# TM4C123AH6PM register map
Vendor: Texas Instruments; File version: 11073
CPU: CM4 r1p2, little endian, no MPU, no FPU, 0x3 interrupt priority bits, 0x0 interrupts
Registers are 32-bit, read-write, no defined reset value unless marked. A register's access mark holds for its fields unless they carry their own. Offsets are from the block's base; [hi:lo] are bit positions; {n}, {i} and the like mark numbered series.

## COMP — Register map for COMP peripheral
Base 0x4003C000; register names take the prefix COMP
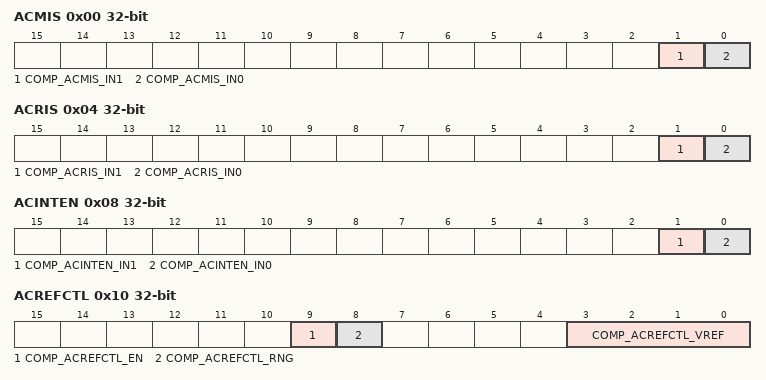
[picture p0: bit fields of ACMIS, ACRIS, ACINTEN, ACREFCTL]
0x00 ACMIS — Analog Comparator Masked Interrupt Status
  [1] COMP_ACMIS_IN1 — Comparator 1 Masked Interrupt Status
  [0] COMP_ACMIS_IN0 — Comparator 0 Masked Interrupt Status
0x04 ACRIS — Analog Comparator Raw Interrupt Status
  [1] COMP_ACRIS_IN1 — Comparator 1 Interrupt Status
  [0] COMP_ACRIS_IN0 — Comparator 0 Interrupt Status
0x08 ACINTEN — Analog Comparator Interrupt Enable
  [1] COMP_ACINTEN_IN1 — Comparator 1 Interrupt Enable
  [0] COMP_ACINTEN_IN0 — Comparator 0 Interrupt Enable
0x10 ACREFCTL — Analog Comparator Reference Voltage Control
  [9] COMP_ACREFCTL_EN — Resistor Ladder Enable
  [8] COMP_ACREFCTL_RNG — Resistor Ladder Range
  [3:0] COMP_ACREFCTL_VREF — Resistor Ladder Voltage Ref
0x20 ACSTAT0 — Analog Comparator Status 0
  [1] COMP_ACSTAT0_OVAL — Comparator Output Value
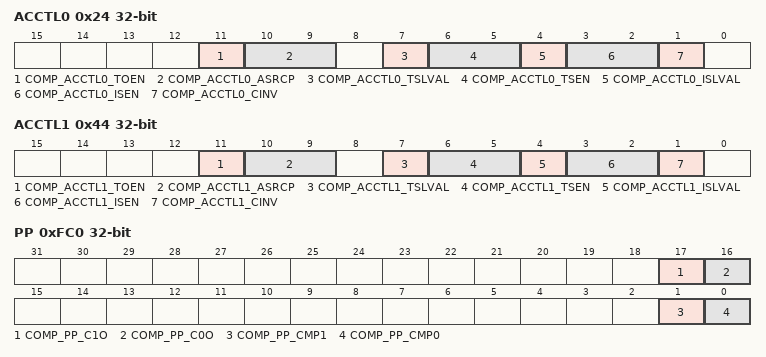
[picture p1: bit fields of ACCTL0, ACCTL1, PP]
0x24 ACCTL0 — Analog Comparator Control 0
  [11] COMP_ACCTL0_TOEN — Trigger Output Enable
  [10:9] COMP_ACCTL0_ASRCP — Analog Source Positive
    0=COMP_ACCTL0_ASRCP_PIN (Pin value of Cn+); 1=COMP_ACCTL0_ASRCP_PIN0 (Pin value of C0+); 2=COMP_ACCTL0_ASRCP_REF (Internal voltage reference)
  [7] COMP_ACCTL0_TSLVAL — Trigger Sense Level Value
  [6:5] COMP_ACCTL0_TSEN — Trigger Sense
    0=COMP_ACCTL0_TSEN_LEVEL (Level sense, see TSLVAL); 1=COMP_ACCTL0_TSEN_FALL (Falling edge); 2=COMP_ACCTL0_TSEN_RISE (Rising edge); 3=COMP_ACCTL0_TSEN_BOTH (Either edge)
  [4] COMP_ACCTL0_ISLVAL — Interrupt Sense Level Value
  [3:2] COMP_ACCTL0_ISEN — Interrupt Sense
    0=COMP_ACCTL0_ISEN_LEVEL (Level sense, see ISLVAL); 1=COMP_ACCTL0_ISEN_FALL (Falling edge); 2=COMP_ACCTL0_ISEN_RISE (Rising edge); 3=COMP_ACCTL0_ISEN_BOTH (Either edge)
  [1] COMP_ACCTL0_CINV — Comparator Output Invert
0x40 ACSTAT1 — Analog Comparator Status 1
  [1] COMP_ACSTAT1_OVAL — Comparator Output Value
0x44 ACCTL1 — Analog Comparator Control 1
  [11] COMP_ACCTL1_TOEN — Trigger Output Enable
  [10:9] COMP_ACCTL1_ASRCP — Analog Source Positive
    0=COMP_ACCTL1_ASRCP_PIN (Pin value of Cn+); 1=COMP_ACCTL1_ASRCP_PIN0 (Pin value of C0+); 2=COMP_ACCTL1_ASRCP_REF (Internal voltage reference (VIREF))
  [7] COMP_ACCTL1_TSLVAL — Trigger Sense Level Value
  [6:5] COMP_ACCTL1_TSEN — Trigger Sense
    0=COMP_ACCTL1_TSEN_LEVEL (Level sense, see TSLVAL); 1=COMP_ACCTL1_TSEN_FALL (Falling edge); 2=COMP_ACCTL1_TSEN_RISE (Rising edge); 3=COMP_ACCTL1_TSEN_BOTH (Either edge)
  [4] COMP_ACCTL1_ISLVAL — Interrupt Sense Level Value
  [3:2] COMP_ACCTL1_ISEN — Interrupt Sense
    0=COMP_ACCTL1_ISEN_LEVEL (Level sense, see ISLVAL); 1=COMP_ACCTL1_ISEN_FALL (Falling edge); 2=COMP_ACCTL1_ISEN_RISE (Rising edge); 3=COMP_ACCTL1_ISEN_BOTH (Either edge)
  [1] COMP_ACCTL1_CINV — Comparator Output Invert
0xFC0 PP — Analog Comparator Peripheral Properties
  [17] COMP_PP_C1O — Comparator Output 1 Present
  [16] COMP_PP_C0O — Comparator Output 0 Present
  [1] COMP_PP_CMP1 — Comparator 1 Present
  [0] COMP_PP_CMP0 — Comparator 0 Present

## EEPROM — Register map for EEPROM peripheral
Base 0x400AF000; register names take the prefix EEPROM
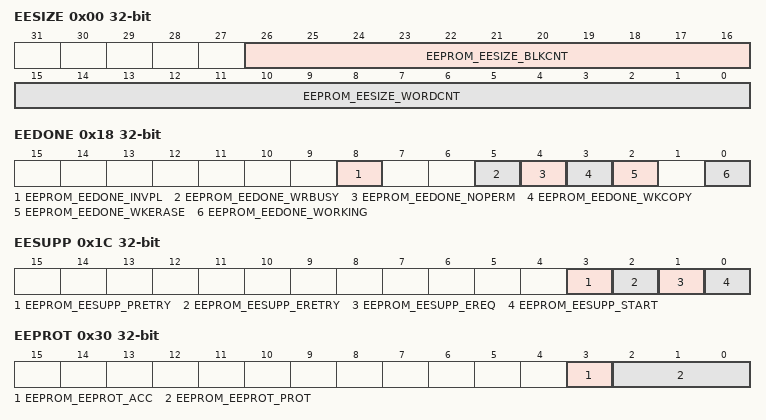
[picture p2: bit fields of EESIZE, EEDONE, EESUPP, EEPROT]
0x00 EESIZE — EEPROM Size Information
  [26:16] EEPROM_EESIZE_BLKCNT — Number of 16-Word Blocks
  [15:0] EEPROM_EESIZE_WORDCNT — Number of 32-Bit Words
0x04 EEBLOCK — EEPROM Current Block
  [15:0] EEPROM_EEBLOCK_BLOCK — Current Block
0x08 EEOFFSET — EEPROM Current Offset
  [3:0] EEPROM_EEOFFSET_OFFSET — Current Address Offset
0x10 EERDWR — EEPROM Read-Write
  [31:0] EEPROM_EERDWR_VALUE — EEPROM Read or Write Data
0x14 EERDWRINC — EEPROM Read-Write with Increment
  [31:0] EEPROM_EERDWRINC_VALUE — EEPROM Read or Write Data with Increment
0x18 EEDONE — EEPROM Done Status
  [8] EEPROM_EEDONE_INVPL — Invalid Program Voltage Level
  [5] EEPROM_EEDONE_WRBUSY — Write Busy
  [4] EEPROM_EEDONE_NOPERM — Write Without Permission
  [3] EEPROM_EEDONE_WKCOPY — Working on a Copy
  [2] EEPROM_EEDONE_WKERASE — Working on an Erase
  [0] EEPROM_EEDONE_WORKING — EEPROM Working
0x1C EESUPP — EEPROM Support Control and Status
  [3] EEPROM_EESUPP_PRETRY — Programming Must Be Retried
  [2] EEPROM_EESUPP_ERETRY — Erase Must Be Retried
  [1] EEPROM_EESUPP_EREQ — Erase Required
  [0] EEPROM_EESUPP_START — Start Erase
0x20 EEUNLOCK — EEPROM Unlock
  [31:0] EEPROM_EEUNLOCK_UNLOCK
0x30 EEPROT — EEPROM Protection
  [3] EEPROM_EEPROT_ACC — Access Control
  [2:0] EEPROM_EEPROT_PROT — Protection Control
    0=EEPROM_EEPROT_PROT_RWNPW (This setting is the default. If there is no password, the block is not protected and is readable and writable); 1=EEPROM_EEPROT_PROT_RWPW (If there is a password, the block is readable or writable only when unlocked); 2=EEPROM_EEPROT_PROT_RONPW (If there is no password, the block is readable, not writable)
{0x34+4i} EEPASS{i} (i=0..2) — EEPROM Password
  [31:0] EEPROM_EEPASS{i}_PASS — Password
0x40 EEINT — EEPROM Interrupt
  [0] EEPROM_EEINT_INT — Interrupt Enable
0x50 EEHIDE — EEPROM Block Hide
  [31:1] EEPROM_EEHIDE_HN — Hide Block
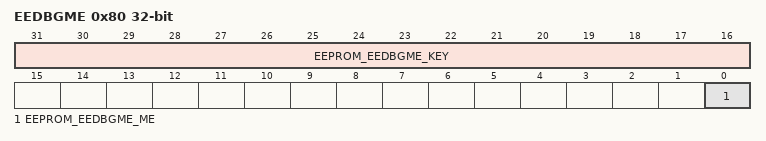
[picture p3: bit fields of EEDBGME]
0x80 EEDBGME — EEPROM Debug Mass Erase
  [31:16] EEPROM_EEDBGME_KEY — Erase Key
  [0] EEPROM_EEDBGME_ME — Mass Erase
0xFC0 PP — EEPROM Peripheral Properties
  [4:0] EEPROM_PP_SIZE — EEPROM Size
